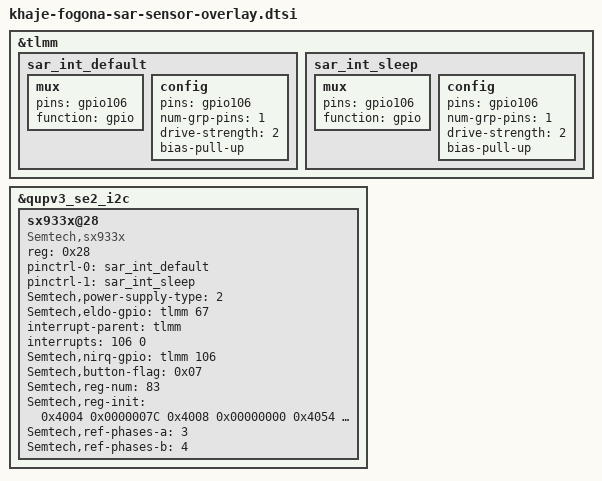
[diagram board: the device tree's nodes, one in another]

&tlmm {
	sar_int_default: sar_int_default {
			mux {
				pins = "gpio106";
				function =  "gpio";
			};
			config {
				pins = "gpio106";
				num-grp-pins = <1>;
				drive-strength = <2>;
				bias-pull-up;
			};
	};

	sar_int_sleep: sar_int_sleep {
			mux {
				pins = "gpio106";
				function =  "gpio";
			};
			config {
				pins = "gpio106";
				num-grp-pins = <1>;
				drive-strength = <2>;
				bias-pull-up;
			};
	};
};

&qupv3_se2_i2c {
	status = "ok";

	sx933x@28 { /* SAR sensor */
		compatible = "Semtech,sx933x";
		reg = <0x28>;
		pinctrl-names = "default","sleep";
		pinctrl-0 = <&sar_int_default>;
		pinctrl-1 = <&sar_int_sleep>;
		Semtech,power-supply-type = <2>;
		Semtech,eldo-gpio = <&tlmm 67 0x00>;
		interrupt-parent = <&tlmm>;
		interrupts = <106 0>;
		interrupt-names = "sx933x_irq";
		Semtech,nirq-gpio= <&tlmm 106 0>;
		Semtech,button-flag = <0x07>;
		Semtech,reg-num = <83>;
		Semtech,reg-init = <
		0x4004 0x0000007C
		0x4008 0x00000000
		0x4054 0x00000400
		0x42C0 0x08000000
		0x42C4 0x0000003F
		0x800C 0x00000000
		0x8010 0x00000000
		0x8014 0x00000000
		0x8018 0x00000000
		0x801C 0x00000031
		0x8020 0x001F001F
		0x8028 0x2C9202E1
		0x802C 0x10000A96
		0x8030 0x249602C0
		0x8034 0x10000A6E
		0x8038 0x25920024
		0x803C 0x10000A6E
		0x8040 0x24B2026A
		0x8044 0x10000A6E
		0x8048 0x249282DD
		0x804C 0x0000088E
		0x8050 0x80001EE6
		0x8054 0x10323701
		0x8058 0x20630030
		0x805C 0x00005000
		0x8060 0x00000000
		0x8064 0x00760000
		0x8068 0x00000000
		0x806C 0x00000000
		0x8070 0x00000000
		0x8074 0x10323701
		0x8078 0x20630030
		0x807C 0x00005000
		0x8080 0x00000000
		0x8084 0x00760000
		0x8088 0x00000000
		0x808C 0x00000000
		0x8090 0x10002805
		0x8094 0x10323701
		0x8098 0x20630030
		0x809C 0x00005000
		0x80A0 0x00000000
		0x80A4 0x00760000
		0x80A8 0x00000000
		0x80AC 0x03000300
		0x80B0 0x00000000
		0x80B4 0x1032FF05
		0x80B8 0x20630060
		0x80BC 0x5000
		0x80C0 0x00000000
		0x80C4 0x00000000
		0x80C8 0x00000000
		0x80CC 0x00200020
		0x80D0 0x00000000
		0x80D4 0x1632FF05
		0x80D8 0x20630030
		0x80DC 0x00005300
		0x80E0 0x00000000
		0x80E4 0x00000000
		0x80E8 0x00000000
		0x80EC 0x00000000
		0x80F0 0x00000000
		0x80F4 0x10162800
		0x80F8 0x20400031
		0x80FC 0x54AC5300
		0x8100 0x00000000
		0x8104 0x00000000
		0x8108 0x00000000
		0x810C 0x00000000
		0x8110 0x00000000
		0x8124 0x0400000B
		0x8128 0x0400000C
		0x812C 0x00000000
		0x8130 0x00000000
		0x8134 0x00000000
		0x8138 0x00000000
		0x813C 0x00000000
		0x8140 0x00000000
		0x8144 0x00000000
		0x8148 0x00000000
		0x814C 0x00000000
		0x81A4 0x01D00018
		0x8024 0x10000A6E
		>;
		Semtech,ref-phases-a = <3>;
		Semtech,ref-phases-b = <4>;
		status = "ok";
	};
};
